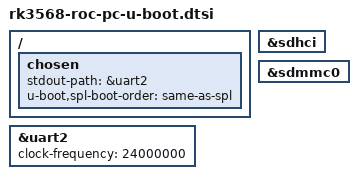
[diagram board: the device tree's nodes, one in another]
// SPDX-License-Identifier: GPL-2.0+
/*
 * (C) Copyright 2021 Rockchip Electronics Co., Ltd
 */

#include "rk356x-u-boot.dtsi"

/ {
	chosen {
		stdout-path = &uart2;
		u-boot,spl-boot-order = "same-as-spl", &sdmmc0, &sdhci;
	};
};

&sdhci {
	u-boot,dm-spl;
	status = "okay";
};

&sdmmc0 {
	u-boot,dm-spl;
	status = "okay";
};

&uart2 {
	clock-frequency = <24000000>;
	u-boot,dm-spl;
	status = "okay";
};
